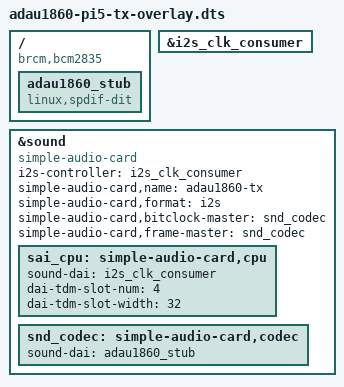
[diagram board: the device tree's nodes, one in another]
// SPDX-License-Identifier: GPL-2.0
//
// ADAU1860 <-> Raspberry Pi 5 / CM5 (RP1) on GPIO 18-21, CODEC IS CLOCK MASTER.
// Intended use here is NOT audio: it is a fixed-rate data pipe for
// accelerometer samples. See DATA_OVER_I2S.md before using it.
//
// Clock direction is chosen by picking the right RP1 block, not by configuring
// one (dwc-i2s.c sets DW_I2S_MASTER or DW_I2S_SLAVE exclusively from a
// synthesis parameter):
//     i2s_clk_producer -> rp1_i2s0   Pi drives BCLK/LRCLK
//     i2s_clk_consumer -> rp1_i2s1   codec drives BCLK/LRCLK   <-- used here
// Both aliases, and their GPIO18-21 pinctrl, are in bcm2712-rpi.dtsi.
//
// The ADAU1860 has no ASoC driver (verified against sound/soc/codecs/Kconfig
// in mainline and in ADI's fork), so a dummy codec stands in and the chip is
// configured entirely over I2C from userspace.
//
// DIRECTION: PLAYBACK -- Pi transmits on GPIO21 (SDOUT) into the ADAU1860.
// CONFIRMED IN USE 2026-09-02: Pi reads the accelerometer and pushes samples
// into the ADAU1860 DSP for processing.
//
// Defaults to TDM4 because dwc-i2s.c accepts a channel count of ONLY 2, 4, 6
// or 8 -- three channels is -EINVAL -- so X/Y/Z needs a 4th slot anyway. Use
// it for a magic word + sequence counter; I2S carries no framing of its own
// and a one-slot slip silently permutes your axes. See DATA_OVER_I2S.md.
//
// Build:   dtc -@ -I dts -O dtb -o adau1860-pi5-tx.dtbo adau1860-pi5-tx-overlay.dts
// Install: sudo cp adau1860-pi5-tx.dtbo /boot/firmware/overlays/
// config.txt:
//     dtparam=i2c_arm=on
//     dtoverlay=adau1860-pi5-tx                      # TDM4 X/Y/Z/seq (default)
//     dtoverlay=adau1860-pi5-tx,slots=8              # 8 slots if you need more

/dts-v1/;
/plugin/;

/ {
	compatible = "brcm,bcm2835";

	fragment@0 {
		target = <&i2s_clk_consumer>;
		__overlay__ {
			status = "okay";
		};
	};

	fragment@1 {
		target-path = "/";
		__overlay__ {
			adau1860_stub: adau1860_stub {
				// Playback-only dummy: spdif_transmitter.c declares
				// .playback and no .capture.
				compatible = "linux,spdif-dit";
				#sound-dai-cells = <0>;
				status = "okay";
			};
		};
	};

	fragment@2 {
		target = <&sound>;
		__overlay__ {
			compatible = "simple-audio-card";
			i2s-controller = <&i2s_clk_consumer>;
			status = "okay";

			simple-audio-card,name = "adau1860-tx";
			simple-audio-card,format = "i2s";

			// The CODEC owns both clocks. This is what makes
			// dw_i2s_set_fmt() request SND_SOC_DAIFMT_BC_FC, which only
			// rp1_i2s1 can satisfy.
			simple-audio-card,bitclock-master = <&snd_codec>;
			simple-audio-card,frame-master = <&snd_codec>;

			sai_cpu: simple-audio-card,cpu {
				sound-dai = <&i2s_clk_consumer>;
				// 2, 4, 6 or 8 ONLY (designware_i2s.h). Max 8, despite
				// the ADAU1860 supporting TDM16.
				dai-tdm-slot-num = <4>;
				// Setting tdm_slots at all forces data_width to 32 in
				// dw_i2s_hw_params(), so use S32_LE.
				dai-tdm-slot-width = <32>;
			};

			snd_codec: simple-audio-card,codec {
				sound-dai = <&adau1860_stub>;
			};
		};
	};

	__overrides__ {
		slots = <&sai_cpu>,"dai-tdm-slot-num:0";
		width = <&sai_cpu>,"dai-tdm-slot-width:0";
	};
};
